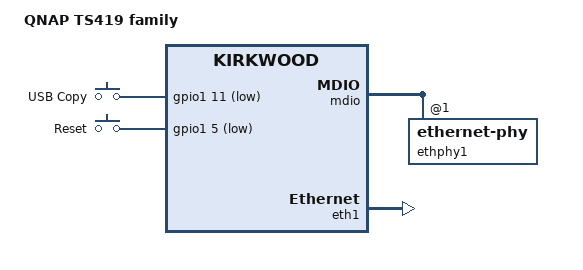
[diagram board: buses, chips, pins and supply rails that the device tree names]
/ {
	model = "QNAP TS419 family";
	compatible = "qnap,ts419", "marvell,kirkwood";
	ocp@f1000000 {
		pinctrl: pin-controller@10000 {
			pinctrl-names = "default";
			pmx_USB_copy_button: pmx-USB-copy-button {
				marvell,pins = "mpp43";
				marvell,function = "gpio";
			};
			pmx_reset_button: pmx-reset-button {
				marvell,pins = "mpp37";
				marvell,function = "gpio";
			};
			pmx_jumper_jp1: pmx-jumper_jp1 {
				marvell,pins = "mpp45";
				marvell,function = "gpio";
			};
		};
	};
	gpio_keys {
		compatible = "gpio-keys";
		#address-cells = <1>;
		#size-cells = <0>;
		pinctrl-0 = <&pmx_reset_button &pmx_USB_copy_button>;
		pinctrl-names = "default";
		copy {
			label = "USB Copy";
			linux,code = <KEY_COPY>;
			gpios = <&gpio1 11 GPIO_ACTIVE_LOW>;
		};
		reset {
			label = "Reset";
			linux,code = <KEY_RESTART>;
			gpios = <&gpio1 5 GPIO_ACTIVE_LOW>;
		};
	};
};
&mdio {
	status = "okay";
	ethphy1: ethernet-phy@1 {
		device_type = "ethernet-phy";
	};
};
&eth1 {
	status = "okay";
	ethernet1-port@0 {
		phy-handle = <&ethphy1>;
	};
};
